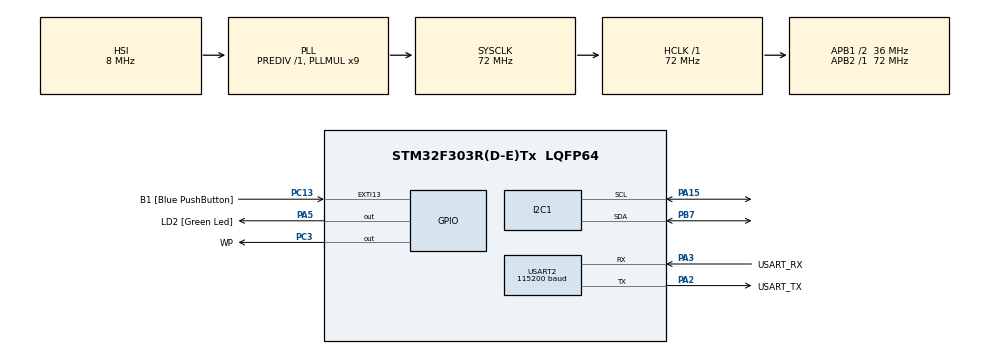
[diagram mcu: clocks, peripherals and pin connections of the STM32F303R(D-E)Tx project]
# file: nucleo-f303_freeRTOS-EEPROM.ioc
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Dma.I2C1_RX.0.Direction=DMA_PERIPH_TO_MEMORY
Dma.I2C1_RX.0.Instance=DMA1_Channel7
Dma.I2C1_RX.0.MemDataAlignment=DMA_MDATAALIGN_BYTE
Dma.I2C1_RX.0.MemInc=DMA_MINC_ENABLE
Dma.I2C1_RX.0.Mode=DMA_NORMAL
Dma.I2C1_RX.0.PeriphDataAlignment=DMA_PDATAALIGN_BYTE
Dma.I2C1_RX.0.PeriphInc=DMA_PINC_DISABLE
Dma.I2C1_RX.0.Priority=DMA_PRIORITY_LOW
Dma.I2C1_TX.1.Direction=DMA_MEMORY_TO_PERIPH
Dma.I2C1_TX.1.Instance=DMA1_Channel6
Dma.I2C1_TX.1.MemDataAlignment=DMA_MDATAALIGN_BYTE
Dma.I2C1_TX.1.MemInc=DMA_MINC_ENABLE
Dma.I2C1_TX.1.Mode=DMA_NORMAL
Dma.I2C1_TX.1.PeriphDataAlignment=DMA_PDATAALIGN_BYTE
Dma.I2C1_TX.1.PeriphInc=DMA_PINC_DISABLE
Dma.I2C1_TX.1.Priority=DMA_PRIORITY_LOW
Dma.Request0=I2C1_RX
Dma.Request1=I2C1_TX
Mcu.Family=STM32F3
Mcu.Name=STM32F303R(D-E)Tx
Mcu.Package=LQFP64
NVIC.DMA1_Channel6_IRQn=true\:0\:0\:false\:false\:true\:false\:true
NVIC.DMA1_Channel7_IRQn=true\:0\:0\:false\:false\:true\:false\:true
NVIC.I2C1_ER_IRQn=true\:0\:0\:false\:false\:true\:true\:true
NVIC.I2C1_EV_IRQn=true\:0\:0\:false\:false\:true\:true\:true
NVIC.PriorityGroup=NVIC_PRIORITYGROUP_0
PA13.GPIO_Label=TMS
PA13.Mode=Serial_Wire
PA13.Signal=SYS_JTMS-SWDIO
PA14.GPIO_Label=TCK
PA14.Mode=Serial_Wire
PA14.Signal=SYS_JTCK-SWCLK
PA15.Mode=I2C
PA15.Signal=I2C1_SCL
PA2.GPIO_Label=USART_TX
PA2.GPIO_Mode=GPIO_MODE_AF_PP
PA2.GPIO_PuPd=GPIO_NOPULL
PA2.GPIO_Speed=GPIO_SPEED_FREQ_LOW
PA2.Mode=Asynchronous
PA2.Signal=USART2_TX
PA3.GPIO_Label=USART_RX
PA3.GPIO_Mode=GPIO_MODE_AF_PP
PA3.GPIO_PuPd=GPIO_NOPULL
PA3.GPIO_Speed=GPIO_SPEED_FREQ_LOW
PA3.Mode=Asynchronous
PA3.Signal=USART2_RX
PA5.GPIO_Label=LD2 [Green Led]
PA5.GPIO_Mode=GPIO_MODE_OUTPUT_PP
PA5.GPIO_PuPd=GPIO_NOPULL
PA5.GPIO_Speed=GPIO_SPEED_FREQ_LOW
PA5.Signal=GPIO_Output
PB3.GPIO_Label=SWO
PB3.Signal=SYS_JTDO-TRACESWO
PB7.Mode=I2C
PB7.Signal=I2C1_SDA
PC13.GPIO_Label=B1 [Blue PushButton]
PC13.GPIO_ModeDefaultEXTI=GPIO_MODE_IT_FALLING
PC13.Signal=GPXTI13
PC14-OSC32_IN.Mode=LSE-External-Oscillator
PC14-OSC32_IN.Signal=RCC_OSC32_IN
PC15-OSC32_OUT.Mode=LSE-External-Oscillator
PC15-OSC32_OUT.Signal=RCC_OSC32_OUT
PC3.GPIO_Label=WP
PC3.Signal=GPIO_Output
PF0-OSC_IN.Mode=HSE-External-Clock-Source
PF0-OSC_IN.Signal=RCC_OSC_IN
PF1-OSC_OUT.Signal=RCC_OSC_OUT
ProjectManager.HeapSize=0x200
ProjectManager.StackSize=0x400
ProjectManager.TargetToolchain=STM32CubeIDE
RCC.AHBFreq_Value=72000000
RCC.APB1CLKDivider=RCC_HCLK_DIV2
RCC.APB1Freq_Value=36000000
RCC.APB1TimFreq_Value=72000000
RCC.APB2Freq_Value=72000000
RCC.APB2TimFreq_Value=72000000
RCC.CortexFreq_Value=72000000
RCC.HCLKFreq_Value=72000000
RCC.HSE_VALUE=8000000
RCC.HSI_VALUE=8000000
RCC.PLLM=8
RCC.PLLMUL=RCC_PLL_MUL9
RCC.PLLN=336
RCC.PLLP=RCC_PLLP_DIV4
RCC.PLLQ=7
RCC.RCC_PLLsource_Clock_Source_FROM_HSE=RCC_HSE_PREDIV_DIV2
RCC.SYSCLKFreq_VALUE=72000000
RCC.SYSCLKSourceVirtual=RCC_SYSCLKSOURCE_PLLCLK
RCC.USBFreq_Value=72000000
USART2.BaudRate=115200
USART2.VirtualMode-Asynchronous=VM_ASYNC
board=NUCLEO-F303RE

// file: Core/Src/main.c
/* USER CODE BEGIN Header */
/**
  ******************************************************************************
  * @file           : main.c
  * @brief          : Main program body
  ******************************************************************************
  * @attention
  *
  * <h2><center>&copy; Copyright (c) 2020 STMicroelectronics.
  * All rights reserved.</center></h2>
  *
  * This software component is licensed by ST under BSD 3-Clause license,
  * the "License"; You may not use this file except in compliance with the
  * License. You may obtain a copy of the License at:
  *                        opensource.org/licenses/BSD-3-Clause
  *
  ******************************************************************************
  */
/* USER CODE END Header */

#include "main.h"

/* USER CODE BEGIN PD */
#define EEPROM_ADDR 0xa0	//shiftattu 1 vasemmalle!
/* USER CODE END PD */

I2C_HandleTypeDef hi2c1;
DMA_HandleTypeDef hdma_i2c1_rx;
DMA_HandleTypeDef hdma_i2c1_tx;

UART_HandleTypeDef huart2;

/* USER CODE BEGIN PV */
uint8_t rxBuffer[32];
uint8_t txBuffer[32];
uint16_t memAddr;

/* USER CODE END PV */

void SystemClock_Config(void);
static void MX_GPIO_Init(void);
static void MX_DMA_Init(void);
static void MX_USART2_UART_Init(void);
static void MX_I2C1_Init(void);

int main(void)
{

  /* MCU Configuration--------------------------------------------------------*/

  /* Reset of all peripherals, Initializes the Flash interface and the Systick. */
  HAL_Init();

  /* Configure the system clock */
  SystemClock_Config();

  /* Initialize all configured peripherals */
  MX_GPIO_Init();
  MX_DMA_Init();
  MX_USART2_UART_Init();
  MX_I2C1_Init();
  /* USER CODE BEGIN 2 */
  HAL_GPIO_WritePin(WP_GPIO_Port, WP_Pin, GPIO_PIN_SET);
  memAddr = 32;
  memAddr = __builtin_bswap16(memAddr);
  HAL_I2C_Master_Transmit(&hi2c1, EEPROM_ADDR, (uint8_t *)&memAddr, sizeof(memAddr), 0xffffffff );
  HAL_I2C_Master_Receive(&hi2c1, EEPROM_ADDR, rxBuffer, 32, 0xffffffff );
  /* USER CODE END 2 */

  /* Infinite loop */
  while (1)
  {

  }
}

void SystemClock_Config(void)
{
  RCC_OscInitTypeDef RCC_OscInitStruct = {0};
  RCC_ClkInitTypeDef RCC_ClkInitStruct = {0};
  RCC_PeriphCLKInitTypeDef PeriphClkInit = {0};

  /** Initializes the CPU, AHB and APB busses clocks
  */
  RCC_OscInitStruct.OscillatorType = RCC_OSCILLATORTYPE_HSI;
  RCC_OscInitStruct.HSIState = RCC_HSI_ON;
  RCC_OscInitStruct.HSICalibrationValue = RCC_HSICALIBRATION_DEFAULT;
  RCC_OscInitStruct.PLL.PLLState = RCC_PLL_ON;
  RCC_OscInitStruct.PLL.PLLSource = RCC_PLLSOURCE_HSI;
  RCC_OscInitStruct.PLL.PLLMUL = RCC_PLL_MUL9;
  RCC_OscInitStruct.PLL.PREDIV = RCC_PREDIV_DIV1;
  if (HAL_RCC_OscConfig(&RCC_OscInitStruct) != HAL_OK)
  {
    Error_Handler();
  }
  /** Initializes the CPU, AHB and APB busses clocks
  */
  RCC_ClkInitStruct.ClockType = RCC_CLOCKTYPE_HCLK|RCC_CLOCKTYPE_SYSCLK
                              |RCC_CLOCKTYPE_PCLK1|RCC_CLOCKTYPE_PCLK2;
  RCC_ClkInitStruct.SYSCLKSource = RCC_SYSCLKSOURCE_PLLCLK;
  RCC_ClkInitStruct.AHBCLKDivider = RCC_SYSCLK_DIV1;
  RCC_ClkInitStruct.APB1CLKDivider = RCC_HCLK_DIV2;
  RCC_ClkInitStruct.APB2CLKDivider = RCC_HCLK_DIV1;

  if (HAL_RCC_ClockConfig(&RCC_ClkInitStruct, FLASH_LATENCY_2) != HAL_OK)
  {
    Error_Handler();
  }
  PeriphClkInit.PeriphClockSelection = RCC_PERIPHCLK_USART2|RCC_PERIPHCLK_I2C1;
  PeriphClkInit.Usart2ClockSelection = RCC_USART2CLKSOURCE_PCLK1;
  PeriphClkInit.I2c1ClockSelection = RCC_I2C1CLKSOURCE_HSI;
  if (HAL_RCCEx_PeriphCLKConfig(&PeriphClkInit) != HAL_OK)
  {
    Error_Handler();
  }
}

static void MX_I2C1_Init(void)
{

  hi2c1.Instance = I2C1;
  hi2c1.Init.Timing = 0x2000090E;
  hi2c1.Init.OwnAddress1 = 0;
  hi2c1.Init.AddressingMode = I2C_ADDRESSINGMODE_7BIT;
  hi2c1.Init.DualAddressMode = I2C_DUALADDRESS_DISABLE;
  hi2c1.Init.OwnAddress2 = 0;
  hi2c1.Init.OwnAddress2Masks = I2C_OA2_NOMASK;
  hi2c1.Init.GeneralCallMode = I2C_GENERALCALL_DISABLE;
  hi2c1.Init.NoStretchMode = I2C_NOSTRETCH_DISABLE;
  if (HAL_I2C_Init(&hi2c1) != HAL_OK)
  {
    Error_Handler();
  }
  /** Configure Analogue filter
  */
  if (HAL_I2CEx_ConfigAnalogFilter(&hi2c1, I2C_ANALOGFILTER_ENABLE) != HAL_OK)
  {
    Error_Handler();
  }
  /** Configure Digital filter
  */
  if (HAL_I2CEx_ConfigDigitalFilter(&hi2c1, 0) != HAL_OK)
  {
    Error_Handler();
  }

}

static void MX_USART2_UART_Init(void)
{

  huart2.Instance = USART2;
  huart2.Init.BaudRate = 115200;
  huart2.Init.WordLength = UART_WORDLENGTH_8B;
  huart2.Init.StopBits = UART_STOPBITS_1;
  huart2.Init.Parity = UART_PARITY_NONE;
  huart2.Init.Mode = UART_MODE_TX_RX;
  huart2.Init.HwFlowCtl = UART_HWCONTROL_NONE;
  huart2.Init.OverSampling = UART_OVERSAMPLING_16;
  huart2.Init.OneBitSampling = UART_ONE_BIT_SAMPLE_DISABLE;
  huart2.AdvancedInit.AdvFeatureInit = UART_ADVFEATURE_NO_INIT;
  if (HAL_UART_Init(&huart2) != HAL_OK)
  {
    Error_Handler();
  }

}

static void MX_DMA_Init(void)
{

  /* DMA controller clock enable */
  __HAL_RCC_DMA1_CLK_ENABLE();

  /* DMA interrupt init */
  /* DMA1_Channel6_IRQn interrupt configuration */
  HAL_NVIC_SetPriority(DMA1_Channel6_IRQn, 0, 0);
  HAL_NVIC_EnableIRQ(DMA1_Channel6_IRQn);
  /* DMA1_Channel7_IRQn interrupt configuration */
  HAL_NVIC_SetPriority(DMA1_Channel7_IRQn, 0, 0);
  HAL_NVIC_EnableIRQ(DMA1_Channel7_IRQn);

}

static void MX_GPIO_Init(void)
{
  GPIO_InitTypeDef GPIO_InitStruct = {0};

  /* GPIO Ports Clock Enable */
  __HAL_RCC_GPIOC_CLK_ENABLE();
  __HAL_RCC_GPIOF_CLK_ENABLE();
  __HAL_RCC_GPIOA_CLK_ENABLE();
  __HAL_RCC_GPIOB_CLK_ENABLE();

  /*Configure GPIO pin Output Level */
  HAL_GPIO_WritePin(WP_GPIO_Port, WP_Pin, GPIO_PIN_RESET);

  /*Configure GPIO pin Output Level */
  HAL_GPIO_WritePin(LD2_GPIO_Port, LD2_Pin, GPIO_PIN_RESET);

  /*Configure GPIO pin : B1_Pin */
  GPIO_InitStruct.Pin = B1_Pin;
  GPIO_InitStruct.Mode = GPIO_MODE_IT_FALLING;
  GPIO_InitStruct.Pull = GPIO_NOPULL;
  HAL_GPIO_Init(B1_GPIO_Port, &GPIO_InitStruct);

  /*Configure GPIO pin : WP_Pin */
  GPIO_InitStruct.Pin = WP_Pin;
  GPIO_InitStruct.Mode = GPIO_MODE_OUTPUT_PP;
  GPIO_InitStruct.Pull = GPIO_NOPULL;
  GPIO_InitStruct.Speed = GPIO_SPEED_FREQ_LOW;
  HAL_GPIO_Init(WP_GPIO_Port, &GPIO_InitStruct);

  /*Configure GPIO pin : LD2_Pin */
  GPIO_InitStruct.Pin = LD2_Pin;
  GPIO_InitStruct.Mode = GPIO_MODE_OUTPUT_PP;
  GPIO_InitStruct.Pull = GPIO_NOPULL;
  GPIO_InitStruct.Speed = GPIO_SPEED_FREQ_LOW;
  HAL_GPIO_Init(LD2_GPIO_Port, &GPIO_InitStruct);

}

void Error_Handler(void)
{
}

/************************ (C) COPYRIGHT STMicroelectronics *****END OF FILE****/
